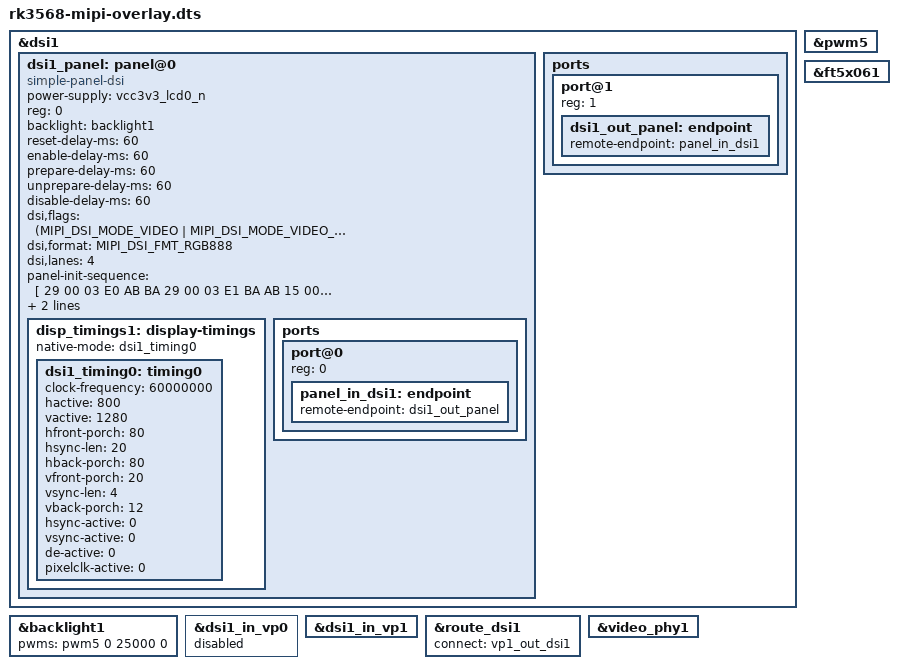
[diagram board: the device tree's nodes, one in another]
/dts-v1/;
/plugin/;

#include <dt-bindings/gpio/gpio.h>
#include <dt-bindings/pinctrl/rockchip.h>
#include <dt-bindings/display/drm_mipi_dsi.h>
#include <dt-bindings/interrupt-controller/irq.h>
#include <dt-bindings/display/media-bus-format.h>

/ {

	fragment@0 {
		target = <&dsi1>;
		__overlay__ {
			status = "disabled";
			dsi1_panel: panel@0 {
				status = "disabled";
				compatible = "simple-panel-dsi";
				power-supply = <&vcc3v3_lcd0_n>;
				reg = <0>;
				backlight = <&backlight1>;
				reset-delay-ms = <60>;
				enable-delay-ms = <60>;
				prepare-delay-ms = <60>;
				unprepare-delay-ms = <60>;
				disable-delay-ms = <60>;
				dsi,flags = <(MIPI_DSI_MODE_VIDEO | MIPI_DSI_MODE_VIDEO_BURST |
					MIPI_DSI_MODE_LPM | MIPI_DSI_MODE_EOT_PACKET)>;
				dsi,format = <MIPI_DSI_FMT_RGB888>;
				dsi,lanes  = <4>;

                panel-init-sequence = [
                        29 00 03 E0 AB BA
                        29 00 03 E1 BA AB
                        15 00 02 B0 00
                        29 00 05 B1 10 01 47 FF
                        29 00 07 B2 0C 0E 04 14 14 14
                        29 00 04 B3 56 D3 00
                        29 00 04 B4 22 30 04
                        15 00 02 B5 00
                        29 00 08 B6 B0 00 00 10 00 10 00
                        29 00 09 B7 0E 00 FF 08 08 FF FF 00
                        29 00 08 B8 05 12 29 49 48 00 00
                        29 00 27 B9 4D 42 38 31 33 27 2F 1B 36 35 35 53 41 49 3D 3D 33 29 26 4C 42 39 31 33 27 2F 1B 36 35 35 53 41 49 3D 3D 33 29 26
                        29 00 09 BA 00 00 00 44 24 00 00 00
                        29 00 04 BB 76 00 00
                        29 00 03 BC 00 00
                        29 00 06 BD FF 00 00 00 00
                        15 00 02 BE 00
                        29 00 11 C0 98 76 12 34 33 33 44 44 06 04 8A 04 0F 00 00 00
                        29 00 0B C1 53 94 02 85 06 04 8A 04 54 00
                        29 00 0D C2 37 09 08 89 08 10 22 21 44 BB 18 00
                        29 00 17 C3 9C 1D 1E 1F 10 12 0C 0E 05 24 24 24 24 24 24 07 24 24 24 24 24 24
                        29 00 17 C4 1C 1D 1E 1F 11 13 0D 0F 04 24 24 24 24 24 24 06 24 24 24 24 24 24
                        29 00 04 C5 E8 85 76
                        29 00 03 C6 20 20
                        29 00 17 C7 41 01 0D 11 09 15 19 4F 10 D7 CF 19 1B 1D 03 02 25 30 00 03 FF 00
                        29 00 07 C8 61 00 31 42 54 16
                        29 00 06 C9 A1 22 FF Cd 23
                        29 00 03 CA 4B 43
                        29 00 05 CC 2E 02 04 08
                        29 00 09 CD 0E 64 64 20 1E 6B 06 83
                        29 00 04 D0 27 10 80
                        29 00 05 D1 00 0D FF 0F
                        29 00 05 D2 E3 2B 38 00
                        29 00 0C D4 00 01 00 0E 04 44 08 10 00 07 00
                        15 00 02 D5 00
                        29 00 03 D6 00 00
                        29 00 05 D7 00 00 00 00
                        29 00 04 E4 08 55 03
                        29 00 09 E6 00 01 FF FF FF FF FF FF
                        29 00 04 E7 00 00 00
                        29 00 08 E8 D5 FF FF FF 00 00 00
                        15 00 02 E9 FF
                        29 00 06 F0 12 03 20 00 FF
                        29 00 1B F1 A6 C8 EA E6 E4 CC E4 BE F0 B2 AA C7 FF 66 98 E3 87 C8 99 C8 8C BE 96 91 8F FF
                        15 00 02 F3 03
                        29 00 1B F4 FF FE FC FA F8 F4 F0 E8 E0 D0 C0 A0 80 7F 5F 3F 2F 1F 17 0F 0B 07 05 03 01 00
                        29 00 1B F5 FF FE FC FA F8 F4 F0 E8 E0 D0 C0 A0 80 7F 5F 3F 2F 1F 17 0F 0B 07 05 03 01 00
                        29 00 1B F6 FF FE FC FA F8 F4 F0 E8 E0 D0 C0 A0 80 7F 5F 3F 2F 1F 17 0F 0B 07 05 03 01 00
                        29 00 08 F7 00 00 00 00 00 00 00
                        29 00 08 F8 00 00 00 00 00 00 00
                        29 00 08 F9 00 00 00 00 00 00 00
                        29 00 1A FA 00 84 12 21 48 48 21 12 84 69 69 5A A5 96 96 A5 5A B7 DE ED 7B 7B ED DE B7
                        29 00 18 FB 00 12 0F FF FF FF 00 38 40 08 70 0B 40 19 50 21 C0 27 60 2D 00 00 0F
                        29 00 03 E3 20 21
                        05 C8 01 11
                        05 14 01 29
                ];

				panel-exit-sequence = [
					05 05 01 28
					05 78 01 10
				];

				disp_timings1: display-timings {
					native-mode = <&dsi1_timing0>;
					dsi1_timing0: timing0 {
						clock-frequency = <60000000>;
						hactive = <800>;
						vactive = <1280>;
						hfront-porch = <80>;
						hsync-len = <20>;
						hback-porch = <80>;
						vfront-porch = <20>;
						vsync-len = <4>;
						vback-porch = <12>;
						hsync-active = <0>;
						vsync-active = <0>;
						de-active = <0>;
						pixelclk-active = <0>;
					};
				};

				ports {
					#address-cells = <1>;
					#size-cells = <0>;
					port@0 {
						reg = <0>;
						panel_in_dsi1: endpoint {
							remote-endpoint = <&dsi1_out_panel>;
						};
					};
				};
			};

			ports {
				#address-cells = <1>;
				#size-cells = <0>;
				port@1 {
					reg = <1>;
					dsi1_out_panel: endpoint {
						remote-endpoint = <&panel_in_dsi1>;
					};
				};
			};
		};
	};

	fragment@1 {
		target = <&pwm5>;
		__overlay__ {
			status = "okay";
		};
	};

	fragment@2 {
		target = <&backlight1>;
		__overlay__ {
			pwms = <&pwm5 0 25000 0>;
			status = "okay";
		};
	};

	fragment@3 {
		target = <&dsi1>;
		__overlay__ {
			status = "okay";
		};
	};

	fragment@4 {
		target = <&dsi1_panel>;
		__overlay__ {
			status = "okay";
		};
	};

	fragment@5 {
		target = <&dsi1_in_vp0>;
		__overlay__ {
			status = "disabled";
		};
	};

	fragment@6 {
		target = <&dsi1_in_vp1>;
		__overlay__ {
			status = "okay";
		};
	};

	fragment@7 {
		target = <&ft5x061>;
		__overlay__ {
			status = "okay";
		};
	};

	fragment@8 {
		target = <&route_dsi1>;
		__overlay__ {
			status = "okay";
			connect = <&vp1_out_dsi1>;
		};
	};

	fragment@9 {
		target = <&video_phy1>;
		__overlay__ {
			status = "okay";
		};
	};
};
